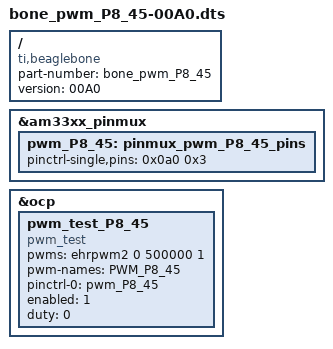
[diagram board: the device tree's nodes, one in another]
/*
 * Copyright (C) 2013 CircuitCo
 * Copyright (C) 2013 Texas Instruments
 *
 * This program is free software; you can redistribute it and/or modify
 * it under the terms of the GNU General Public License version 2 as
 * published by the Free Software Foundation.
 */
/dts-v1/;
/plugin/;

/ {
	compatible = "ti,beaglebone";

	/* identification */
	part-number = "bone_pwm_P8_45";
	version = "00A0";

	fragment@0 {
		target = <&am33xx_pinmux>;
		__overlay__ {
			pwm_P8_45: pinmux_pwm_P8_45_pins {
				pinctrl-single,pins = <0x0a0  0x3>; /* P8_45 (ZCZ ball R1) | MODE 3 */
			};
		};
	};

	fragment@1 {
		target = <&ocp>;
		__overlay__ {
			pwm_test_P8_45 {
				compatible	= "pwm_test";
				pwms 		= <&ehrpwm2 0 500000 1>;
				pwm-names 	= "PWM_P8_45";
			    pinctrl-names	= "default";
			    pinctrl-0	= <&pwm_P8_45>;
				enabled		= <1>;
				duty		= <0>;
				status 		= "okay";
			};
		};
	};
};
